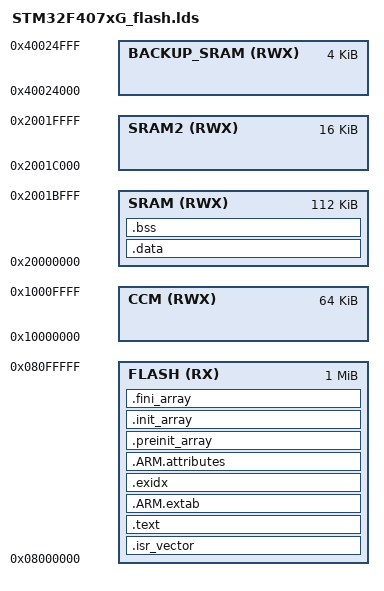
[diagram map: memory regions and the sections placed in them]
/* Generated by LinkerScriptGenerator [http://visualgdb.com/LinkerScriptGenerator]
 * Target: STM32F407xG
 * The file is provided under the BSD license.
 */

ENTRY(Reset_Handler)

MEMORY
{
	FLASH (RX)        : ORIGIN = 0x08000000, LENGTH = 1M
	SRAM (RWX)        : ORIGIN = 0x20000000, LENGTH = 112K
	SRAM2 (RWX)       : ORIGIN = 0x2001c000, LENGTH = 16K
	CCM (RWX)         : ORIGIN = 0x10000000, LENGTH = 64K
	BACKUP_SRAM (RWX) : ORIGIN = 0x40024000, LENGTH = 4K
}

_estack = 0x2001c000;

SECTIONS
{
	.isr_vector :
	{
		. = ALIGN(4);
		KEEP(*(.isr_vector))
		. = ALIGN(4);
	} > FLASH

	.text :
	{
		. = ALIGN(4);
		_stext = .;

		*(.text)
		*(.text*)
		*(.rodata)
		*(.rodata*)
		*(.glue_7)
		*(.glue_7t)
		KEEP(*(.init))
		KEEP(*(.fini))
		. = ALIGN(4);
		_etext = .;

	} > FLASH

	__exidx_start = .;
    .ARM.exidx :
    {
        *(.ARM.exidx* .gnu.linkonce.armexidx.*)
    } > rom
    __exidx_end = .;
	
	.ARM.extab :
	{
		. = ALIGN(4);
		*(.ARM.extab)
		*(.gnu.linkonce.armextab.*)
		. = ALIGN(4);
	} > FLASH

	.exidx :
	{
		. = ALIGN(4);
		PROVIDE(__exidx_start__ = .);
		*(.ARM.exidx*)
		. = ALIGN(4);
		PROVIDE(__exidx_end__ = .);
	} > FLASH

	.ARM.attributes :
	{
		*(.ARM.attributes)
	} > FLASH

	.preinit_array :
	{
		PROVIDE(__preinit_array_start__ = .);
		KEEP(*(.preinit_array*))
		PROVIDE(__preinit_array_end__ = .);
	} > FLASH

	.init_array :
	{
		PROVIDE(__init_array_start__ = .);
		KEEP(*(SORT(.init_array.*)))
		KEEP(*(.init_array*))
		PROVIDE(__init_array_end__ = .);
	} > FLASH

	.fini_array :
	{
		PROVIDE(__fini_array_start__ = .);
		KEEP(*(.fini_array*))
		KEEP(*(SORT(.fini_array.*)))
		PROVIDE(__fini_array_end__ = .);
	} > FLASH

	_sidata = .;

	.data : AT(_sidata)
	{
		. = ALIGN(4);
		_sdata = .;

		PROVIDE(__data_start__ = _sdata);
		*(.data)
		*(.data*)
		. = ALIGN(4);
		_edata = .;

		PROVIDE(__data_end__ = _sdata);
	} > SRAM

	.bss :
	{
		. = ALIGN(4);
		_sbss = .;

		PROVIDE(__bss_start__ = _sbss);
		*(.bss)
		*(.bss*)
		*(COMMON)
		. = ALIGN(4);
		_ebss = .;

		PROVIDE(__bss_end__ = _sbss);
	} > SRAM

	PROVIDE(end = .);

}

